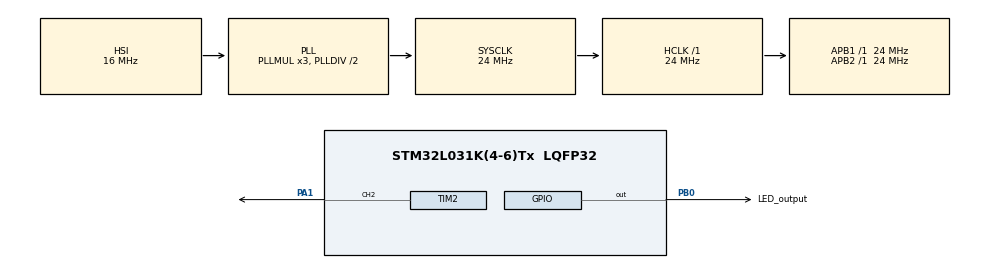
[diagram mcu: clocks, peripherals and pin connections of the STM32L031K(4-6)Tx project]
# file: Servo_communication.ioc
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Mcu.Family=STM32L0
Mcu.Name=STM32L031K(4-6)Tx
Mcu.Package=LQFP32
PA1.Signal=S_TIM2_CH2
PA13.Mode=Serial_Wire
PA13.Signal=SYS_SWDIO
PA14.Mode=Serial_Wire
PA14.Signal=SYS_SWCLK
PB0.GPIO_Label=LED_output
PB0.Signal=GPIO_Output
ProjectManager.HeapSize=0x200
ProjectManager.StackSize=0x400
ProjectManager.TargetToolchain=STM32CubeIDE
RCC.AHBFreq_Value=24000000
RCC.APB1Freq_Value=24000000
RCC.APB1TimFreq_Value=24000000
RCC.APB2Freq_Value=24000000
RCC.APB2TimFreq_Value=24000000
RCC.HCLKFreq_Value=24000000
RCC.HSE_VALUE=8000000
RCC.HSI16_VALUE=16000000
RCC.HSI_VALUE=16000000
RCC.LSE_VALUE=32768
RCC.MSI_VALUE=2097000
RCC.SYSCLKFreq_VALUE=24000000
RCC.SYSCLKSource=RCC_SYSCLKSOURCE_PLLCLK
RCC.VCOOutputFreq_Value=48000000
SH.S_TIM2_CH2.0=TIM2_CH2,PWM Generation2 CH2
TIM2.Channel-PWM\ Generation2\ CH2=TIM_CHANNEL_2
TIM2.Period=10000-1
TIM2.Prescaler=24-1
VP_TIM2_VS_ClockSourceINT.Mode=Internal
board=custom

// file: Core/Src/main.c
/* USER CODE BEGIN Header */
/**
  ******************************************************************************
  * @file           : main.c
  * @brief          : Main program body
  ******************************************************************************
  * @attention
  *
  * Copyright (c) 2024 STMicroelectronics.
  * All rights reserved.
  *
  * This software is licensed under terms that can be found in the LICENSE file
  * in the root directory of this software component.
  * If no LICENSE file comes with this software, it is provided AS-IS.
  *
  ******************************************************************************
  */
/* USER CODE END Header */
#include "main.h"

TIM_HandleTypeDef htim2;

void SystemClock_Config(void);
static void MX_GPIO_Init(void);
static void MX_TIM2_Init(void);

/* USER CODE BEGIN 0 */

void setServoAngle(uint32_t angle){
	if(angle > 180) angle = 180;
	int32_t minPulseWidth = 1000; //1ms pulse width at a 1MHz clock
	int32_t maxPulseWidth = 2000; //2ms pulse width
	uint32_t pulse = (uint32_t)((angle * (maxPulseWidth - minPulseWidth)) /180) + minPulseWidth;
	TIM2->CCR2 = pulse;
}

/* USER CODE END 0 */

int main(void)
{

  /* MCU Configuration--------------------------------------------------------*/

  /* Reset of all peripherals, Initializes the Flash interface and the Systick. */
  HAL_Init();

  /* Configure the system clock */
  SystemClock_Config();

  /* Initialize all configured peripherals */
  MX_GPIO_Init();
  MX_TIM2_Init();
  /* USER CODE BEGIN 2 */
  HAL_TIM_PWM_Start(&htim2, TIM_CHANNEL_2);
  /* USER CODE END 2 */

  /* Infinite loop */
  /* USER CODE BEGIN WHILE */
  while (1)
  {
	  HAL_GPIO_TogglePin(LED_output_GPIO_Port, LED_output_Pin);
	  if(clockwise){
		  angle--;
	  }
	  else{
		  angle++;
	  }
	  setServoAngle(angle);
	  HAL_Delay(2);
	  if(angle >= 180 || angle < 0){
		  clockwise = (clockwise) ? 0 : 1;
	  }
    /* USER CODE END WHILE */

  }
}

void SystemClock_Config(void)
{
  RCC_OscInitTypeDef RCC_OscInitStruct = {0};
  RCC_ClkInitTypeDef RCC_ClkInitStruct = {0};

  /** Configure the main internal regulator output voltage
  */
  __HAL_PWR_VOLTAGESCALING_CONFIG(PWR_REGULATOR_VOLTAGE_SCALE1);

  /** Initializes the RCC Oscillators according to the specified parameters
  * in the RCC_OscInitTypeDef structure.
  */
  RCC_OscInitStruct.OscillatorType = RCC_OSCILLATORTYPE_HSI;
  RCC_OscInitStruct.HSIState = RCC_HSI_ON;
  RCC_OscInitStruct.HSICalibrationValue = RCC_HSICALIBRATION_DEFAULT;
  RCC_OscInitStruct.PLL.PLLState = RCC_PLL_ON;
  RCC_OscInitStruct.PLL.PLLSource = RCC_PLLSOURCE_HSI;
  RCC_OscInitStruct.PLL.PLLMUL = RCC_PLLMUL_3;
  RCC_OscInitStruct.PLL.PLLDIV = RCC_PLLDIV_2;
  if (HAL_RCC_OscConfig(&RCC_OscInitStruct) != HAL_OK)
  {
    Error_Handler();
  }

  /** Initializes the CPU, AHB and APB buses clocks
  */
  RCC_ClkInitStruct.ClockType = RCC_CLOCKTYPE_HCLK|RCC_CLOCKTYPE_SYSCLK
                              |RCC_CLOCKTYPE_PCLK1|RCC_CLOCKTYPE_PCLK2;
  RCC_ClkInitStruct.SYSCLKSource = RCC_SYSCLKSOURCE_PLLCLK;
  RCC_ClkInitStruct.AHBCLKDivider = RCC_SYSCLK_DIV1;
  RCC_ClkInitStruct.APB1CLKDivider = RCC_HCLK_DIV1;
  RCC_ClkInitStruct.APB2CLKDivider = RCC_HCLK_DIV1;

  if (HAL_RCC_ClockConfig(&RCC_ClkInitStruct, FLASH_LATENCY_1) != HAL_OK)
  {
    Error_Handler();
  }
}

static void MX_TIM2_Init(void)
{

  TIM_ClockConfigTypeDef sClockSourceConfig = {0};
  TIM_MasterConfigTypeDef sMasterConfig = {0};
  TIM_OC_InitTypeDef sConfigOC = {0};

  htim2.Instance = TIM2;
  htim2.Init.Prescaler = 24-1;
  htim2.Init.CounterMode = TIM_COUNTERMODE_UP;
  htim2.Init.Period = 10000-1;
  htim2.Init.ClockDivision = TIM_CLOCKDIVISION_DIV1;
  htim2.Init.AutoReloadPreload = TIM_AUTORELOAD_PRELOAD_DISABLE;
  if (HAL_TIM_Base_Init(&htim2) != HAL_OK)
  {
    Error_Handler();
  }
  sClockSourceConfig.ClockSource = TIM_CLOCKSOURCE_INTERNAL;
  if (HAL_TIM_ConfigClockSource(&htim2, &sClockSourceConfig) != HAL_OK)
  {
    Error_Handler();
  }
  if (HAL_TIM_PWM_Init(&htim2) != HAL_OK)
  {
    Error_Handler();
  }
  sMasterConfig.MasterOutputTrigger = TIM_TRGO_RESET;
  sMasterConfig.MasterSlaveMode = TIM_MASTERSLAVEMODE_DISABLE;
  if (HAL_TIMEx_MasterConfigSynchronization(&htim2, &sMasterConfig) != HAL_OK)
  {
    Error_Handler();
  }
  sConfigOC.OCMode = TIM_OCMODE_PWM1;
  sConfigOC.Pulse = 0;
  sConfigOC.OCPolarity = TIM_OCPOLARITY_HIGH;
  sConfigOC.OCFastMode = TIM_OCFAST_DISABLE;
  if (HAL_TIM_PWM_ConfigChannel(&htim2, &sConfigOC, TIM_CHANNEL_2) != HAL_OK)
  {
    Error_Handler();
  }
  HAL_TIM_MspPostInit(&htim2);

}

static void MX_GPIO_Init(void)
{
  GPIO_InitTypeDef GPIO_InitStruct = {0};

  /* GPIO Ports Clock Enable */
  __HAL_RCC_GPIOA_CLK_ENABLE();
  __HAL_RCC_GPIOB_CLK_ENABLE();

  /*Configure GPIO pin Output Level */
  HAL_GPIO_WritePin(LED_output_GPIO_Port, LED_output_Pin, GPIO_PIN_RESET);

  /*Configure GPIO pin : LED_output_Pin */
  GPIO_InitStruct.Pin = LED_output_Pin;
  GPIO_InitStruct.Mode = GPIO_MODE_OUTPUT_PP;
  GPIO_InitStruct.Pull = GPIO_NOPULL;
  GPIO_InitStruct.Speed = GPIO_SPEED_FREQ_LOW;
  HAL_GPIO_Init(LED_output_GPIO_Port, &GPIO_InitStruct);

}

void Error_Handler(void)
{
  __disable_irq();
  while (1)
  {
  }
}
